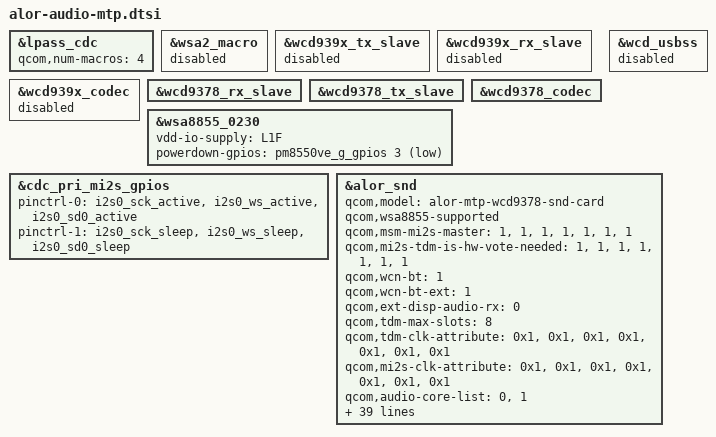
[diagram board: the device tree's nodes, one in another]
//
/* Copyright (c) Qualcomm Technologies, Inc. and/or its subsidiaries.
 *  SPDX-License-Identifier: BSD-3-Clause-Clear
 */

#include "lpass-audio-cdc-1.0.dtsi"
#include "alor-lpi.dtsi"
#include "lpass-audio-bt-swr.dtsi"
#include "lpass-cdc-gpio.dtsi"
#include "alor-audio-lpass-reg.dtsi"
#include "wcd939x.dtsi"
#include "canoe-audio-simple-amp.dtsi"

&lpass_cdc {
	qcom,num-macros = <4>;
};

&wsa2_macro {
	status = "disabled";
};

&wcd939x_tx_slave {
	status = "disabled";
};

&wcd939x_rx_slave {
	status = "disabled";
};

&wcd939x_codec {
	status = "disabled";
	/* 0 for digital crosstalk disabled,
	 * 1 for digital crosstalk with local sensed a-xtalk enabled, and
	 * 2 for digital crosstalk with remote sensed a-xtalk enabled.
	 */
};

&wcd9378_rx_slave {
	status = "okay";
};

&wcd9378_tx_slave {
	status = "okay";
};

&wcd9378_codec {
	status = "okay";
};

/* This needs to be un commented */
&wcd_usbss {
	status = "disabled";
};

&wsa8855_0230 {
	vdd-io-supply = <&L1F>;
	powerdown-gpios = <&pm8550ve_g_gpios 3 GPIO_ACTIVE_LOW>;
};

&cdc_pri_mi2s_gpios {
	status = "okay";
	pinctrl-0 = <&i2s0_sck_active &i2s0_ws_active
			&i2s0_sd0_active>;
	pinctrl-1 = <&i2s0_sck_sleep &i2s0_ws_sleep
			&i2s0_sd0_sleep>;
};

&alor_snd {
	qcom,model = "alor-mtp-wcd9378-snd-card";
	qcom,wsa8855-supported;
	qcom,msm-mi2s-master = <1>, <1>, <1>, <1>, <1>, <1>, <1>;
	qcom,mi2s-tdm-is-hw-vote-needed = <1>, <1>, <1>, <1>, <1>, <1>, <1>;
	qcom,wcn-bt = <1>;
	qcom,wcn-bt-ext = <1>;
	qcom,ext-disp-audio-rx = <0>;
	qcom,tdm-max-slots = <8>;
	qcom,tdm-clk-attribute = <0x1>, <0x1>, <0x1>, <0x1>, <0x1>, <0x1>, <0x1>;
	qcom,mi2s-clk-attribute = <0x1>, <0x1>, <0x1>, <0x1>, <0x1>, <0x1>, <0x1>;
	qcom,audio-core-list = <0>, <1>;
	qcom,msm-mbhc-hs-mic-max-threshold-mv = <1670>;
	qcom,msm-mbhc-usbc-audio-supported = <0>;
	qcom,msm-mbhc-hphl-swh = <1>;
	qcom,msm-mbhc-gnd-swh = <1>;
	asoc-codec  = <&stub_codec>, <&lpass_cdc>,
			<&wcd9378_codec>, <&wsa8855_0230>;
	asoc-codec-names = "msm-stub-codec.1", "lpass-cdc",
			"wcd9378_codec", "sdca-simple-amp.01";
	qcom,audio-routing =
			"AMIC2", "Analog Mic2",
			"AMIC2", "MIC BIAS2",
			"VA AMIC2", "Analog Mic2",
			"VA AMIC2", "VA MIC BIAS2",
			"TX DMIC0", "Digital Mic0",
			"TX DMIC0", "MIC BIAS1",
			"TX DMIC1", "Digital Mic1",
			"TX DMIC1", "MIC BIAS1",
			"TX DMIC2", "Digital Mic2",
			"TX DMIC2", "MIC BIAS3",
			"TX DMIC3", "Digital Mic3",
			"TX DMIC3", "MIC BIAS3",
			"IN1_HPHL", "HPHL_OUT",
			"IN2_HPHR", "HPHR_OUT",
			"IN3_AUX", "AUX_OUT",
			"WSA SRC0_INP", "SRC0",
			"WSA_TX DEC0_INP", "TX DEC0 MUX",
			"WSA_TX DEC1_INP", "TX DEC1 MUX",
			"RX_TX DEC0_INP", "TX DEC0 MUX",
			"RX_TX DEC1_INP", "TX DEC1 MUX",
			"RX_TX DEC2_INP", "TX DEC2 MUX",
			"RX_TX DEC3_INP", "TX DEC3 MUX",
			"SA1 AMP IN", "WSA_SPK1 OUT",
			"SA1 AMP IN", "WSA_SPK2 OUT",
			"VA SWR_INPUT", "VA_SWR_CLK",
			"VA_AIF1 CAP", "VA_SWR_CLK",
			"VA_AIF2 CAP", "VA_SWR_CLK",
			"VA_AIF3 CAP", "VA_SWR_CLK",
			"VA DMIC0", "Digital Mic0",
			"VA DMIC1", "Digital Mic1",
			"VA DMIC2", "Digital Mic2",
			"VA DMIC3", "Digital Mic3",
			"VA DMIC0", "VA MIC BIAS1",
			"VA DMIC1", "VA MIC BIAS1",
			"VA DMIC2", "VA MIC BIAS3",
			"VA DMIC3", "VA MIC BIAS3";
	qcom,wsa-max-devs = <1>;
	/*
	 * Add this property,
	 * To Enable swr haptics through OPCM port.
	 * This will include wsa2 dailinks.
	 */
	qcom,cdc-dmic01-gpios = <&cdc_dmic01_gpios>;
	qcom,cdc-dmic23-gpios = <&cdc_dmic23_gpios>;
	qcom,pri-mi2s-gpios = <&cdc_pri_mi2s_gpios>;
	qcom,msm_audio_ssr_devs = <&audio_gpr>, <&lpi_tlmm>,
				  <&lpass_cdc>, <&lpass_bt_swr>;

		/*
		 * ====================
		 * UPD backend - WSA
		 * ====================
		 *
		 * Mute/Unmute the interpolator
		 * ------------------------------
		 * Register:Â LPASS_WSA_CDC_RX0_RX_PATH_MIX_CTL - 0x6B00418
		 *
		 * Send control commands to the peripheral from the soundwire controller
		 * -----------------------------------------------------------------------
		 * Register: LPASS_WSA_SWR_MSTR_WSA_SWRM_CPUn_CMD_FIFO_WR_CMD - 0x6B14020
		 *
		 * Enable/Disable ear piece
		 * --------------------------
		 * Register:Â DIG_CTRL0_PA_FSM_EN - 0x3430
		 *
		 *
		 *	qcom,upd_backends_used = "wsa";
		 *	qcom,upd_lpass_reg_addr = <0x6B00418 0x6B14020>;
		 *	qcom,upd_ear_pa_reg_addr = <0x3430>;
		 *
		 *
		 * ====================
		 * UPD backend - WCD
		 * ====================
		 *
		 * Mute/Unmute the interpolator
		 * ------------------------------
		 * Register: LPASS_WCD_CDC_RX0_RX_PATH_MIX_CTL - 0x6AC0418
		 *
		 * Send control commands to the wcd from the soundwire controller
		 * ----------------------------------------------------------------
		 * Register: LPASS_WCD_SWR_MSTR_WSA_SWRM_CPUn_CMD_FIFO_WR_CMD - 0x7634020
		 *
		 * Enable/Disable ear piece
		 * --------------------------
		 * Register:Â DIG_CTRL0_PA_FSM_EN - 0x300A
		 *
		 */
	qcom,upd_backends_used = "wcd";
	qcom,upd_lpass_reg_addr = <0x6AC0418 0x7634020>;
	qcom,upd_ear_pa_reg_addr = <0x300A>;
};
